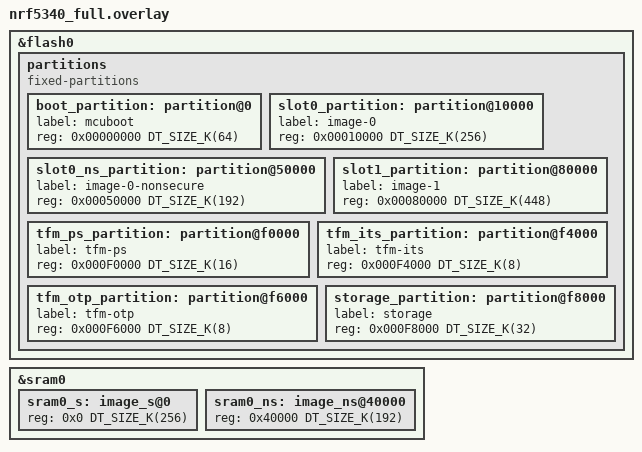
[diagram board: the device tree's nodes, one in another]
/*
 * Copyright (c) 2026 Nordic Semiconductor ASA
 *
 * SPDX-License-Identifier: LicenseRef-Nordic-5-Clause
 */

/*
 * Full-featured TF-M partition layout with MCUboot for nRF5340
 *
 * nRF5340 has 1024 kB of flash and 512 kB of SRAM (application core).
 * TrustZone flash region alignment: 16 kB (SPU-based)
 * TrustZone RAM region alignment:    8 kB
 * Flash erase-block-size:            4 kB
 *
 * IMPORTANT: All secure/non-secure partition boundaries must be
 * aligned to 16 kB in flash. Partition sizes that cross an S/NS
 * boundary must be multiples of 16 kB. This layout follows the
 * upstream TF-M reference layout for nRF5340.
 *
 * This layout enables all TF-M services with MCUboot:
 * - MCUboot bootloader (64 kB)
 * - Primary slot with secure + non-secure sub-partitions
 * - Secondary slot for DFU (same size as primary)
 * - Protected Storage, ITS, OTP partitions
 * - Non-secure storage for application data
 *
 * Suitable for: full-featured IoT devices, development boards
 */

&flash0 {
	partitions {
		compatible = "fixed-partitions";
		#address-cells = <1>;
		#size-cells = <1>;

		/*
		 * Flash layout (S/NS boundaries 16 kB aligned):
		 *
		 * 0x00000000  MCUboot bootloader       (64 kB)
		 * 0x00010000  Primary slot            (448 kB):
		 *   0x00010000  Secure image           (256 kB)
		 *   0x00050000  Non-secure image       (192 kB)
		 * 0x00080000  Secondary slot          (448 kB):
		 *   0x00080000  Secure secondary       (256 kB)
		 *   0x000C0000  Non-secure secondary   (192 kB)
		 * 0x000F0000  TF-M PS                  (16 kB)
		 * 0x000F4000  TF-M ITS                  (8 kB)
		 * 0x000F6000  TF-M OTP / NV counters    (8 kB)
		 * 0x000F8000  Non-secure storage       (32 kB)
		 *
		 * Total: 64 + 448 + 448 + 16 + 8 + 8 + 32 = 1024 kB
		 */

		boot_partition: partition@0 {
			label = "mcuboot";
			reg = <0x00000000 DT_SIZE_K(64)>;
		};

		/* Primary slot with secure/non-secure sub-partitions */
		slot0_partition: partition@10000 {
			label = "image-0";
			reg = <0x00010000 DT_SIZE_K(256)>;
		};

		slot0_ns_partition: partition@50000 {
			label = "image-0-nonsecure";
			reg = <0x00050000 DT_SIZE_K(192)>;
		};

		/* Secondary slot for DFU */
		slot1_partition: partition@80000 {
			label = "image-1";
			reg = <0x00080000 DT_SIZE_K(448)>;
		};

		tfm_ps_partition: partition@f0000 {
			label = "tfm-ps";
			reg = <0x000F0000 DT_SIZE_K(16)>;
		};

		tfm_its_partition: partition@f4000 {
			label = "tfm-its";
			reg = <0x000F4000 DT_SIZE_K(8)>;
		};

		tfm_otp_partition: partition@f6000 {
			label = "tfm-otp";
			reg = <0x000F6000 DT_SIZE_K(8)>;
		};

		storage_partition: partition@f8000 {
			label = "storage";
			reg = <0x000F8000 DT_SIZE_K(32)>;
		};
	};
};

&sram0 {
	sram0_s: image_s@0 {
		#address-cells = <1>;
		#size-cells = <1>;
		reg = <0x0 DT_SIZE_K(256)>;
		ranges = <0x0 0x0 DT_SIZE_K(256)>;
	};

	sram0_ns: image_ns@40000 {
		#address-cells = <1>;
		#size-cells = <1>;
		reg = <0x40000 DT_SIZE_K(192)>;
		ranges = <0x0 0x40000 DT_SIZE_K(192)>;
	};
};
